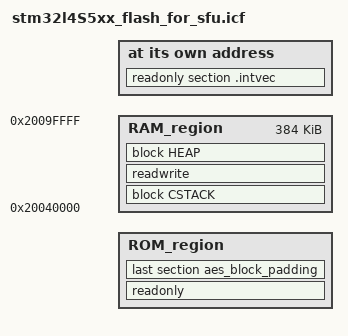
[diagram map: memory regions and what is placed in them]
/*###ICF### Section handled by ICF editor, don't touch! ****/
/*-Editor annotation file-*/
/* IcfEditorFile="$TOOLKIT_DIR$\config\ide\IcfEditor\cortex_v1_0.xml" */
/*-Specials-*/
define memory mem with size = 4G;


/******************************************************************************/
/*       Include of SBSFU symbols file                                        */
/*   (Project>Options>Linker>Extra Options --config_search option is used to  */
/*   specify the the directory to search for include files                    */
/******************************************************************************/
include "mapping_sbsfu.icf";
include "mapping_fwimg.icf";

define symbol __ICFEDIT_intvec_start__ =  __ICFEDIT_region_SLOT_0_start__ + 2048;
export symbol __ICFEDIT_intvec_start__;
/*-Memory Regions-*/
define symbol __ICFEDIT_region_ROM_start__   = __ICFEDIT_intvec_start__;
define symbol __ICFEDIT_region_ROM_end__     = __ICFEDIT_region_SLOT_0_end__ ;
define symbol __ICFEDIT_region_RAM_start__   = 0x20040000; /* SRAM3 */
define symbol __ICFEDIT_region_RAM_end__     = 0x2009FFFF; /* SRAM3 */
define symbol __ICFEDIT_region_SRAM2_start__ = 0x20030000; /* SRAM2 */
define symbol __ICFEDIT_region_SRAM2_end__   = 0x2003FFFF; /* SRAM2 */

/* to make sure the binary size is a multiple of the AES block size (16 bytes) */
define root section aes_block_padding with alignment=16
{
udata8 "Force Alignment";
pad_to 16;
};

/*-Sizes-*/
define symbol __ICFEDIT_size_cstack__ = 0x1900;
define symbol __ICFEDIT_size_heap__   = 0x0;
/**** End of ICF editor section. ###ICF###*/

/* Definition of the static memory section for TLS certificates, keys, and wifi configuration data at the end of the first bank:
 * Provision of 32Kbytes at the end of the second bank. */
define symbol __ICFEDIT_region_FIXED_LOC_start__ = __ICFEDIT_region_SWAP_end__ + 1 ;
export symbol __ICFEDIT_region_FIXED_LOC_start__;

define region ROM_region      = mem:[from __ICFEDIT_region_ROM_start__   to __ICFEDIT_region_SLOT_0_end__ ] ;
define region RAM_region      = mem:[from __ICFEDIT_region_RAM_start__   to __ICFEDIT_region_RAM_end__];

define block CSTACK    with alignment = 8, size = __ICFEDIT_size_cstack__   { };
define block HEAP      with alignment = 8, size = __ICFEDIT_size_heap__     { };

initialize by copy { readwrite };
do not initialize  { section .noinit };

place at address mem:__ICFEDIT_intvec_start__ { readonly section .intvec };

place in ROM_region   { readonly, last section aes_block_padding};
place in RAM_region   { block CSTACK,
                        readwrite,
                        block HEAP };
